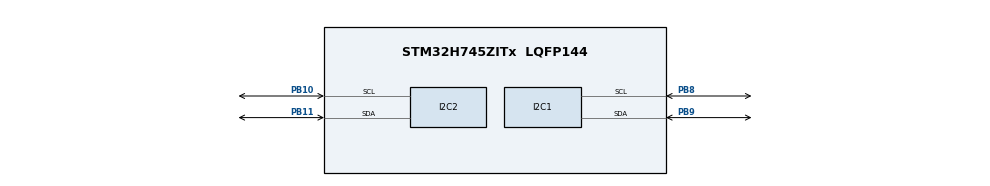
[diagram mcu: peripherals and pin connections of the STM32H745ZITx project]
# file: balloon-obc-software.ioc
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CORTEX_M4.MPU_Control=__NULL
CortexM4.IPs=BDMA,CORTEX_M4\:I,DEBUG,DMA,FATFS_M4\:I,FREERTOS_M4\:I,GPIO,IWDG2\:I,MDMA,NVIC2\:I,OPENAMP_M4\:I,PDM2PCM_M4\:I,PWR,RCC,RESMGR_UTILITY,SYS_M4\:I,USB_DEVICE_M4\:I,USB_HOST_M4\:I,VREFBUF,WWDG2\:I
CortexM7.IPs=BDMA\:I,CORTEX_M7\:I,DEBUG\:I,DMA\:I,FATFS_M7\:I,FREERTOS_M7\:I,GPIO\:I,IWDG1\:I,MDMA\:I,NVIC1\:I,OPENAMP_M7\:I,PDM2PCM_M7\:I,PWR\:I,RCC\:I,RESMGR_UTILITY\:I,SYS\:I,USB_DEVICE_M7\:I,USB_HOST_M7\:I,VREFBUF\:I,WWDG1\:I,I2C1\:I,I2C2\:I
FREERTOS_M4.Tasks01=defaultTask,24,128,StartDefaultTask,Default,NULL,Dynamic,NULL,NULL
FREERTOS_M4.configUSE_NEWLIB_REENTRANT=1
FREERTOS_M7.Tasks01=defaultTask,24,128,StartDefaultTask,Default,NULL,Dynamic,NULL,NULL
FREERTOS_M7.configUSE_NEWLIB_REENTRANT=1
I2C1.Timing=0x00707CBB
I2C2.Timing=0x00707CBB
Mcu.Family=STM32H7
Mcu.Name=STM32H745ZITx
Mcu.Package=LQFP144
NVIC1.PriorityGroup=NVIC_PRIORITYGROUP_4
NVIC2.PriorityGroup=NVIC_PRIORITYGROUP_4
PB10.GPIO_Pu=GPIO_PULLUP
PB10.GPIO_Speed=GPIO_SPEED_FREQ_VERY_HIGH
PB10.Mode=I2C
PB10.PinAttribute=CortexM7
PB10.Signal=I2C2_SCL
PB11.GPIO_Pu=GPIO_PULLUP
PB11.GPIO_Speed=GPIO_SPEED_FREQ_VERY_HIGH
PB11.Mode=I2C
PB11.PinAttribute=CortexM7
PB11.Signal=I2C2_SDA
PB8.GPIO_Pu=GPIO_PULLUP
PB8.GPIO_Speed=GPIO_SPEED_FREQ_VERY_HIGH
PB8.Mode=I2C
PB8.PinAttribute=CortexM7
PB8.Signal=I2C1_SCL
PB9.GPIO_Pu=GPIO_PULLUP
PB9.GPIO_Speed=GPIO_SPEED_FREQ_VERY_HIGH
PB9.Mode=I2C
PB9.PinAttribute=CortexM7
PB9.Signal=I2C1_SDA
ProjectManager.HeapSize=M4-0x200,M7-0x200
ProjectManager.StackSize=M4-0x400,M7-0x400
ProjectManager.TargetToolchain=STM32CubeIDE
RCC.ADCFreq_Value=129000000
RCC.APB1Freq_Value=32000000
RCC.APB2Freq_Value=64000000
RCC.APB3Freq_Value=64000000
RCC.APB4Freq_Value=64000000
RCC.CortexFreq_Value=64000000
RCC.D2PPRE1=RCC_APB1_DIV2
RCC.HCLKFreq_Value=64000000
RCC.SYSCLKFreq_VALUE=64000000
RCC.USBFreq_Value=129000000
SYS.userName=SYS_M7
VP_FREERTOS_M4_VS_CMSIS_V2.Mode=CMSIS_V2
VP_FREERTOS_M7_VS_CMSIS_V2.Mode=CMSIS_V2
VP_SYS_M4_VS_Systick.Mode=SysTick
board=custom

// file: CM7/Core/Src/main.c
/* USER CODE BEGIN Header */
/*
 * 401 Balloon OBC
 * Copyright (C) 2023 BLUEsat and contributors
 *
 * This program is free software: you can redistribute it and/or modify it
 * under the terms of the GNU General Public License as published by the Free
 * Software Foundation, either version 3 of the License, or (at your option)
 * any later version.
 *
 * This program is distributed in the hope that it will be useful, but WITHOUT
 * ANY WARRANTY; without even the implied warranty of MERCHANTABILITY or
 * FITNESS FOR A PARTICULAR PURPOSE. See the GNU General Public License for
 * more details.
 *
 * You should have received a copy of the GNU General Public License along with
 * this program. If not, see <https://www.gnu.org/licenses/>.
 */
/* USER CODE END Header */
#include "main.h"
#include "cmsis_os.h"

/* USER CODE BEGIN Includes */
#include "cppmain.hpp"
/* USER CODE END Includes */

/* USER CODE BEGIN PD */

#ifndef HSEM_ID_0
#    define HSEM_ID_0 (0U) /* HW semaphore 0*/
#endif

/* USER CODE END PD */

I2C_HandleTypeDef hi2c1;
I2C_HandleTypeDef hi2c2;

/* Definitions for defaultTask */
osThreadId_t defaultTaskHandle;
const osThreadAttr_t defaultTask_attributes = {
  .name = "defaultTask",
  .stack_size = 128 * 4,
  .priority = (osPriority_t) osPriorityNormal,
};

void SystemClock_Config(void);
static void MX_GPIO_Init(void);
static void MX_I2C1_Init(void);
static void MX_I2C2_Init(void);
void StartDefaultTask(void *argument);

int main(void)
{
/* USER CODE BEGIN Boot_Mode_Sequence_0 */
    int32_t timeout;
/* USER CODE END Boot_Mode_Sequence_0 */

/* USER CODE BEGIN Boot_Mode_Sequence_1 */
    /* Wait until CPU2 boots and enters in stop mode or timeout*/
    timeout = 0xFFFF;
    while ((__HAL_RCC_GET_FLAG(RCC_FLAG_D2CKRDY) != RESET) && (timeout-- > 0))
        ;
    if (timeout < 0) Error_Handler();
/* USER CODE END Boot_Mode_Sequence_1 */
  /* MCU Configuration--------------------------------------------------------*/

  /* Reset of all peripherals, Initializes the Flash interface and the Systick. */
  HAL_Init();

  /* Configure the system clock */
  SystemClock_Config();
/* USER CODE BEGIN Boot_Mode_Sequence_2 */
    /* When system initialization is finished, Cortex-M7 will release Cortex-M4
    by means of HSEM notification */
    /*HW semaphore Clock enable*/
    __HAL_RCC_HSEM_CLK_ENABLE();
    /*Take HSEM */
    HAL_HSEM_FastTake(HSEM_ID_0);
    /*Release HSEM in order to notify the CPU2(CM4)*/
    HAL_HSEM_Release(HSEM_ID_0, 0);
    /* wait until CPU2 wakes up from stop mode */
    timeout = 0xFFFF;
    while ((__HAL_RCC_GET_FLAG(RCC_FLAG_D2CKRDY) == RESET) && (timeout-- > 0))
        ;
    if (timeout < 0) Error_Handler();
/* USER CODE END Boot_Mode_Sequence_2 */

  /* Initialize all configured peripherals */
  MX_GPIO_Init();
  MX_I2C1_Init();
  MX_I2C2_Init();

  /* Init scheduler */
  osKernelInitialize();

  /* Create the thread(s) */
  /* creation of defaultTask */
  defaultTaskHandle = osThreadNew(StartDefaultTask, NULL, &defaultTask_attributes);

  /* USER CODE BEGIN RTOS_THREADS */
    CppMain();
  /* USER CODE END RTOS_THREADS */

  /* Start scheduler */
  osKernelStart();

  /* We should never get here as control is now taken by the scheduler */
  /* Infinite loop */
    while (1) {

    }
}

void SystemClock_Config(void)
{
  RCC_OscInitTypeDef RCC_OscInitStruct = {0};
  RCC_ClkInitTypeDef RCC_ClkInitStruct = {0};

  /** Supply configuration update enable
  */
  HAL_PWREx_ConfigSupply(PWR_DIRECT_SMPS_SUPPLY);

  /** Configure the main internal regulator output voltage
  */
  __HAL_PWR_VOLTAGESCALING_CONFIG(PWR_REGULATOR_VOLTAGE_SCALE3);

  while(!__HAL_PWR_GET_FLAG(PWR_FLAG_VOSRDY)) {}

  /** Initializes the RCC Oscillators according to the specified parameters
  * in the RCC_OscInitTypeDef structure.
  */
  RCC_OscInitStruct.OscillatorType = RCC_OSCILLATORTYPE_HSI;
  RCC_OscInitStruct.HSIState = RCC_HSI_DIV1;
  RCC_OscInitStruct.HSICalibrationValue = RCC_HSICALIBRATION_DEFAULT;
  RCC_OscInitStruct.PLL.PLLState = RCC_PLL_NONE;
  if (HAL_RCC_OscConfig(&RCC_OscInitStruct) != HAL_OK)
  {
    Error_Handler();
  }

  /** Initializes the CPU, AHB and APB buses clocks
  */
  RCC_ClkInitStruct.ClockType = RCC_CLOCKTYPE_HCLK|RCC_CLOCKTYPE_SYSCLK
                              |RCC_CLOCKTYPE_PCLK1|RCC_CLOCKTYPE_PCLK2
                              |RCC_CLOCKTYPE_D3PCLK1|RCC_CLOCKTYPE_D1PCLK1;
  RCC_ClkInitStruct.SYSCLKSource = RCC_SYSCLKSOURCE_HSI;
  RCC_ClkInitStruct.SYSCLKDivider = RCC_SYSCLK_DIV1;
  RCC_ClkInitStruct.AHBCLKDivider = RCC_HCLK_DIV1;
  RCC_ClkInitStruct.APB3CLKDivider = RCC_APB3_DIV1;
  RCC_ClkInitStruct.APB1CLKDivider = RCC_APB1_DIV2;
  RCC_ClkInitStruct.APB2CLKDivider = RCC_APB2_DIV1;
  RCC_ClkInitStruct.APB4CLKDivider = RCC_APB4_DIV1;

  if (HAL_RCC_ClockConfig(&RCC_ClkInitStruct, FLASH_LATENCY_1) != HAL_OK)
  {
    Error_Handler();
  }
}

static void MX_I2C1_Init(void)
{

  hi2c1.Instance = I2C1;
  hi2c1.Init.Timing = 0x00707CBB;
  hi2c1.Init.OwnAddress1 = 0;
  hi2c1.Init.AddressingMode = I2C_ADDRESSINGMODE_7BIT;
  hi2c1.Init.DualAddressMode = I2C_DUALADDRESS_DISABLE;
  hi2c1.Init.OwnAddress2 = 0;
  hi2c1.Init.OwnAddress2Masks = I2C_OA2_NOMASK;
  hi2c1.Init.GeneralCallMode = I2C_GENERALCALL_DISABLE;
  hi2c1.Init.NoStretchMode = I2C_NOSTRETCH_DISABLE;
  if (HAL_I2C_Init(&hi2c1) != HAL_OK)
  {
    Error_Handler();
  }

  /** Configure Analogue filter
  */
  if (HAL_I2CEx_ConfigAnalogFilter(&hi2c1, I2C_ANALOGFILTER_ENABLE) != HAL_OK)
  {
    Error_Handler();
  }

  /** Configure Digital filter
  */
  if (HAL_I2CEx_ConfigDigitalFilter(&hi2c1, 0) != HAL_OK)
  {
    Error_Handler();
  }

}

static void MX_I2C2_Init(void)
{

  hi2c2.Instance = I2C2;
  hi2c2.Init.Timing = 0x00707CBB;
  hi2c2.Init.OwnAddress1 = 0;
  hi2c2.Init.AddressingMode = I2C_ADDRESSINGMODE_7BIT;
  hi2c2.Init.DualAddressMode = I2C_DUALADDRESS_DISABLE;
  hi2c2.Init.OwnAddress2 = 0;
  hi2c2.Init.OwnAddress2Masks = I2C_OA2_NOMASK;
  hi2c2.Init.GeneralCallMode = I2C_GENERALCALL_DISABLE;
  hi2c2.Init.NoStretchMode = I2C_NOSTRETCH_DISABLE;
  if (HAL_I2C_Init(&hi2c2) != HAL_OK)
  {
    Error_Handler();
  }

  /** Configure Analogue filter
  */
  if (HAL_I2CEx_ConfigAnalogFilter(&hi2c2, I2C_ANALOGFILTER_ENABLE) != HAL_OK)
  {
    Error_Handler();
  }

  /** Configure Digital filter
  */
  if (HAL_I2CEx_ConfigDigitalFilter(&hi2c2, 0) != HAL_OK)
  {
    Error_Handler();
  }

}

static void MX_GPIO_Init(void)
{

  /* GPIO Ports Clock Enable */
  __HAL_RCC_GPIOB_CLK_ENABLE();

}

void StartDefaultTask(void *argument)
{
  /* USER CODE BEGIN 5 */
    /* Infinite loop */
    for (;;) osDelay(1);
  /* USER CODE END 5 */
}

void Error_Handler(void)
{
  /* USER CODE BEGIN Error_Handler_Debug */
    /* User can add his own implementation to report the HAL error return state
     */
    __disable_irq();
    while (1) {}
  /* USER CODE END Error_Handler_Debug */
}

#ifdef  USE_FULL_ASSERT
/**
  * @brief  Reports the name of the source file and the source line number
  *         where the assert_param error has occurred.
  * @param  file: pointer to the source file name
  * @param  line: assert_param error line source number
  * @retval None
  */
void assert_failed(uint8_t *file, uint32_t line)
{
  /* USER CODE BEGIN 6 */
    /* User can add his own implementation to report the file name and line
       number, ex: printf("Wrong parameters value: file %s on line %d\r\n",
       file, line) */
  /* USER CODE END 6 */
}
#endif /* USE_FULL_ASSERT */
